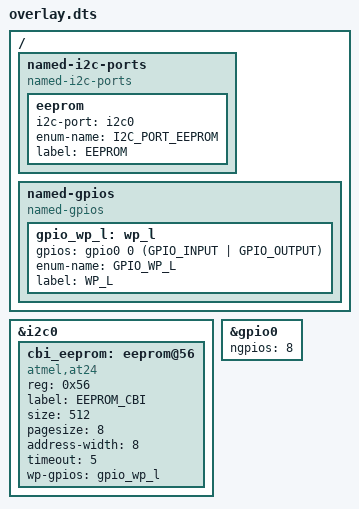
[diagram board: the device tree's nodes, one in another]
/* Copyright 2021 The Chromium OS Authors. All rights reserved.
 * Use of this source code is governed by a BSD-style license that can be
 * found in the LICENSE file.
 */

#include <dt-bindings/gpio_defines.h>

/* i2c0 and gpio0 come from boards/posix/native_posix/native_posix.dts */
/ {
	named-i2c-ports {
		compatible = "named-i2c-ports";
		eeprom {
			i2c-port = <&i2c0>;
			enum-name = "I2C_PORT_EEPROM";
			label = "EEPROM";
		};
	};

	named-gpios {
		compatible = "named-gpios";
		/* In test WP is output because CBI use it, but it is also
		 * input, because test_all_tags set it to enable write
		 * protection.
		 */
		gpio_wp_l: wp_l {
			#gpio-cells = <0>;
			gpios = <&gpio0 0 (GPIO_INPUT | GPIO_OUTPUT)>;
			enum-name = "GPIO_WP_L";
			label = "WP_L";
		};
	};
};

&i2c0 {
	cbi_eeprom: eeprom@56 {
		compatible = "atmel,at24";
		reg = <0x56>;
		label = "EEPROM_CBI";
		size = <512>;
		pagesize = <8>;
		address-width = <8>;
		timeout = <5>;
		wp-gpios = <&gpio_wp_l>;
	};
};

&gpio0 {
	ngpios = <8>;
};
